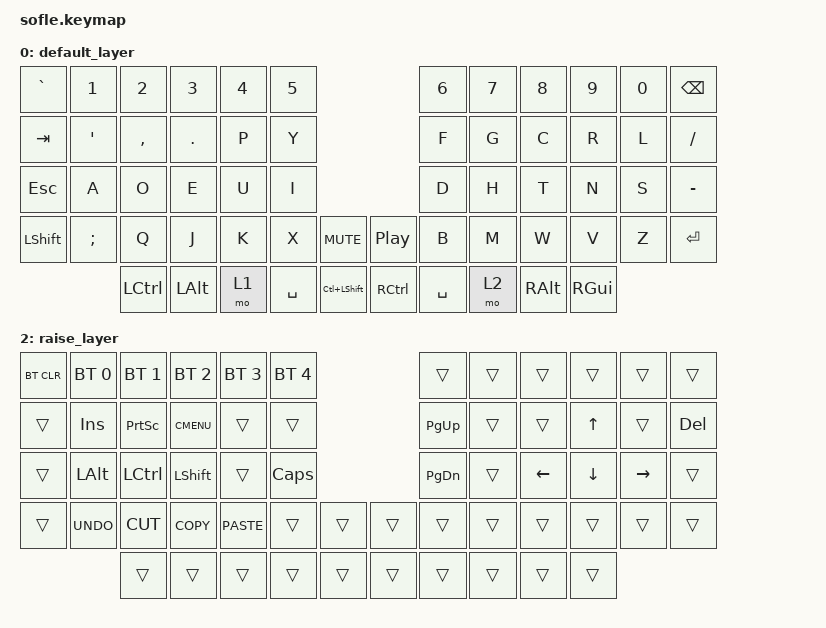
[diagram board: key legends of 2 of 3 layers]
/*
 * Copyright (c) 2020 The ZMK Contributors
 *
 * SPDX-License-Identifier: MIT
 */

#include <behaviors.dtsi>
#include <dt-bindings/zmk/keys.h>
#include <dt-bindings/zmk/bt.h>
#include <dt-bindings/zmk/rgb.h>
#include <dt-bindings/zmk/ext_power.h>
#include <dt-bindings/led/led.h>
#include <dt-bindings/zmk/pointing.h>
&pinctrl {
    spi3_default: spi3_default {
        group1 {
            psels = <NRF_PSEL(SPIM_MOSI, 0, 8)>;
        };
    };

    spi3_sleep: spi3_sleep {
        group1 {
            psels = <NRF_PSEL(SPIM_MOSI, 0, 8)>;
            low-power-enable;
        };
    };
};

&spi3 {
  compatible = "nordic,nrf-spim";
  status = "okay";

  pinctrl-0 = <&spi3_default>;
  pinctrl-1 = <&spi3_sleep>;
  pinctrl-names = "default", "sleep";

  led_strip: ws2812@0 {
    compatible = "worldsemi,ws2812-spi";

    /* SPI */
    reg = <0>; /* ignored, but necessary for SPI bindings */
    spi-max-frequency = <4000000>;

    /* WS2812 */
    chain-length = <10>; /* number of LEDs */
    spi-one-frame = <0x70>;
    spi-zero-frame = <0x40>;
    color-mapping = <LED_COLOR_ID_GREEN
                          LED_COLOR_ID_RED
                          LED_COLOR_ID_BLUE>;
  };
};
         &led_strip {
    chain-length = <30>;
};
/ {
    behaviors {
        // Left encoder: CW = Ctrl+Shift+Right, CCW = Ctrl+Shift+Left.
        scroll_encoder: scroll_encoder {
            compatible = "zmk,behavior-sensor-rotate";
            #sensor-binding-cells = <0>;
            bindings = <&kp LC(LS(RIGHT))>, <&kp LC(LS(LEFT))>;
        };
    };

    keymap {
        compatible = "zmk,keymap";

        default_layer {
// ------------------------------------------------------------------------------------------------------------
// |  `    |  1  |  2  |  3   |  4   |  5   |                         |  6   |  7    |  8    |  9   |   0   |   DEL    |
// |  TAB  |  '  |  ,  |  .   |  P   |  Y   |                         |  F   |  G    |  C    |  R   |   L   | / |
// |  ESC  |  A  |  O  |  E   |  U   |  I   |                         |  D   |  H    |  T    |  N   |   S   |   -   |
// | SHIFT |  ;  |  Q  |  J   |  K   |  X   |  MUTE  |        | ExtPw |  B   |  M    |  W    |  V   |   Z   | ENTER |
//               | LS(CTRL) | ALT  | CTRL | LOWER|  SPACE |        | SPACE | RAISE| CTRL  | ALT   | GUI  |
    bindings = <
    &kp GRAVE &kp N1 &kp N2   &kp N3   &kp N4    &kp N5                                       &kp N6 &kp N7    &kp N8    &kp N9   &kp N0   &kp BSPC
    &kp TAB   &kp SQT &kp COMMA &kp DOT   &kp P    &kp Y                               &kp F  &kp G     &kp C     &kp R    &kp L    &kp FSLH
    &kp ESC   &kp A   &kp O     &kp E    &kp U    &kp I                               &kp D  &kp H     &kp T     &kp N    &kp S    &kp MINUS
    &kp LSHFT &kp SEMI &kp Q   &kp J    &kp K    &kp X   &kp C_MUTE  &kp C_PP &kp B  &kp M     &kp W     &kp V    &kp Z    &kp ENTER
                &kp LCTRL   &kp LALT   &mo 1   &kp SPACE &kp LC(LSHIFT)  &kp RCTRL &kp SPACE &mo 2 &kp RALT  &kp RGUI
    >;

    sensor-bindings = <&scroll_encoder &inc_dec_kp C_VOL_UP C_VOL_DN>;
};

        lower_layer {
// TODO: Some binds are waiting for shifted keycode support.
// ------------------------------------------------------------------------------------------------------------
// |       |  F1 |  F2 |  F3  |  F4  |  F5  |                   |  F6  |  F7   |  F8   |  F9  |  F10  |  F11  |
// | `     |   1 |   2 |   3  |   4  |   5  |                   |   6  |   7   |   8   |  (  |    )  |  F12  |
// |       |  !  |  @  |  #   |  $   |  %   |                   |  ^   |  &    |  *    |  [   |   ]   |   \   |
// |       |  =  |  -  |  +   |  {   |  }   |        |  |       |  [   |  ]    |  ;    |  {   |   }   |  \     |
//               |     |      |      |      |        |  |       |      |       |       |      |
            bindings = <
    &trans    &kp F1    &kp F2    &kp F3      &kp F4    &kp F5                    &kp F6    &kp F7   &kp F8   &kp F9    &kp EQUAL   &kp F11
    &kp GRAVE &kp N1    &kp N2    &kp N3      &kp N4    &kp N5                     &kp N6    &kp N7   &kp N8   &kp N9  &kp N0 &kp F12
    &trans    &kp EXCL  &kp AT    &kp HASH    &kp DLLR  &kp PRCNT                 &kp CARET &kp AMPS  &trans &kp LBKT &kp RBKT  &kp BSLH
    &trans    &kp EQUAL &kp MINUS &kp KP_PLUS    &trans  &trans  &trans   &trans &kp LBKT  &kp RBKT &kp LBRC &kp RBRC  &trans  &kp BSLH
                &trans  &trans    &trans      &trans    &trans    &trans   &trans &trans    &trans   &trans   &trans
    >;

    sensor-bindings = <&scroll_encoder &inc_dec_kp C_VOL_UP C_VOL_DN>;
        };

        raise_layer {
// ------------------------------------------------------------------------------------------------------------
// |BTCLR| BT1  | BT2  |  BT3  |  BT4  |  BT5 |                |      |      |       |      |       |       |
// |     | INS  | PSCR | GUI   |       |      |                | PGUP |      |       |   ^  |       |  DEL  |
// |     | ALT  | CTRL | SHIFT |       | CAPS |                | PGDN |      |   <-  |   v  |   ->  | BKSPC |
// |     | UNDO | CUT  | COPY  | PASTE |      |      |  |      |      |      |       |      |       |       |
//              |      |       |       |      |      |  |      |      |      |       |      |
            bindings = <
    &bt BT_CLR &bt BT_SEL 0 &bt BT_SEL 1 &bt BT_SEL 2 &bt BT_SEL 3 &bt BT_SEL 4             &trans &trans &trans &trans &trans  &trans
    &trans     &kp INS      &kp PSCRN    &kp K_CMENU  &trans       &trans                   &kp PG_UP &trans    &trans  &kp UP      &trans  &kp DEL
    &trans     &kp LALT     &kp LCTRL    &kp LSHFT    &trans       &kp CLCK                 &kp PG_DN  &trans &kp LEFT  &kp DOWN &kp RIGHT &trans
    &trans     &kp K_UNDO   &kp K_CUT    &kp K_COPY   &kp K_PASTE  &trans  &trans   &trans  &trans    &trans    &trans   &trans    &trans  &trans
                        &trans       &trans       &trans       &trans  &trans   &trans  &trans    &trans    &trans   &trans
    >;

    sensor-bindings = <&scroll_encoder &inc_dec_kp C_VOL_UP C_VOL_DN>;
        };
    };
};
